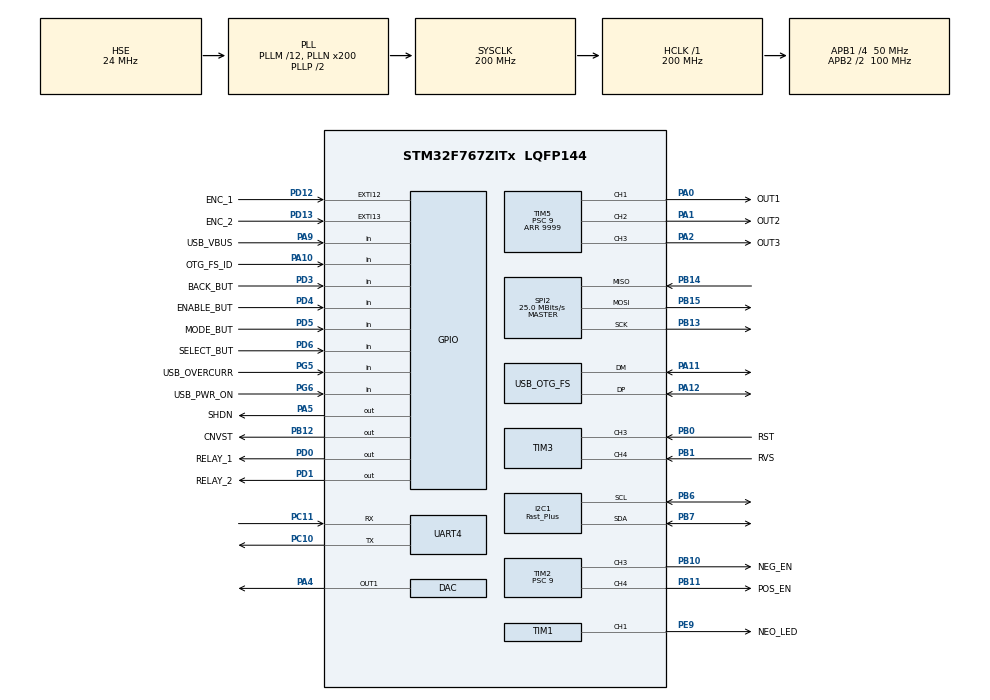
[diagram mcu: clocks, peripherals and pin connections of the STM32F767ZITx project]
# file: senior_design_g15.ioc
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Dma.Request0=TIM5_CH2
Dma.Request1=TIM5_CH3/UP
Dma.Request2=TIM2_UP/CH3
Dma.Request3=TIM2_CH2/CH4
Dma.Request4=TIM1_CH1
Dma.TIM1_CH1.4.Direction=DMA_MEMORY_TO_PERIPH
Dma.TIM1_CH1.4.FIFOMode=DMA_FIFOMODE_DISABLE
Dma.TIM1_CH1.4.Instance=DMA2_Stream1
Dma.TIM1_CH1.4.MemDataAlignment=DMA_MDATAALIGN_HALFWORD
Dma.TIM1_CH1.4.MemInc=DMA_MINC_ENABLE
Dma.TIM1_CH1.4.Mode=DMA_NORMAL
Dma.TIM1_CH1.4.PeriphDataAlignment=DMA_PDATAALIGN_HALFWORD
Dma.TIM1_CH1.4.PeriphInc=DMA_PINC_DISABLE
Dma.TIM1_CH1.4.Priority=DMA_PRIORITY_LOW
Dma.TIM2_CH2/CH4.3.Direction=DMA_MEMORY_TO_PERIPH
Dma.TIM2_CH2/CH4.3.FIFOMode=DMA_FIFOMODE_DISABLE
Dma.TIM2_CH2/CH4.3.Instance=DMA1_Stream6
Dma.TIM2_CH2/CH4.3.MemDataAlignment=DMA_MDATAALIGN_WORD
Dma.TIM2_CH2/CH4.3.MemInc=DMA_MINC_ENABLE
Dma.TIM2_CH2/CH4.3.Mode=DMA_CIRCULAR
Dma.TIM2_CH2/CH4.3.PeriphDataAlignment=DMA_PDATAALIGN_WORD
Dma.TIM2_CH2/CH4.3.PeriphInc=DMA_PINC_DISABLE
Dma.TIM2_CH2/CH4.3.Priority=DMA_PRIORITY_LOW
Dma.TIM2_UP/CH3.2.Direction=DMA_MEMORY_TO_PERIPH
Dma.TIM2_UP/CH3.2.FIFOMode=DMA_FIFOMODE_DISABLE
Dma.TIM2_UP/CH3.2.Instance=DMA1_Stream1
Dma.TIM2_UP/CH3.2.MemDataAlignment=DMA_MDATAALIGN_WORD
Dma.TIM2_UP/CH3.2.MemInc=DMA_MINC_ENABLE
Dma.TIM2_UP/CH3.2.Mode=DMA_CIRCULAR
Dma.TIM2_UP/CH3.2.PeriphDataAlignment=DMA_PDATAALIGN_WORD
Dma.TIM2_UP/CH3.2.PeriphInc=DMA_PINC_DISABLE
Dma.TIM2_UP/CH3.2.Priority=DMA_PRIORITY_LOW
Dma.TIM5_CH2.0.Direction=DMA_MEMORY_TO_PERIPH
Dma.TIM5_CH2.0.FIFOMode=DMA_FIFOMODE_DISABLE
Dma.TIM5_CH2.0.Instance=DMA1_Stream4
Dma.TIM5_CH2.0.MemDataAlignment=DMA_MDATAALIGN_WORD
Dma.TIM5_CH2.0.MemInc=DMA_MINC_ENABLE
Dma.TIM5_CH2.0.Mode=DMA_CIRCULAR
Dma.TIM5_CH2.0.PeriphDataAlignment=DMA_PDATAALIGN_WORD
Dma.TIM5_CH2.0.PeriphInc=DMA_PINC_DISABLE
Dma.TIM5_CH2.0.Priority=DMA_PRIORITY_LOW
Dma.TIM5_CH3/UP.1.Direction=DMA_MEMORY_TO_PERIPH
Dma.TIM5_CH3/UP.1.FIFOMode=DMA_FIFOMODE_DISABLE
Dma.TIM5_CH3/UP.1.Instance=DMA1_Stream0
Dma.TIM5_CH3/UP.1.MemDataAlignment=DMA_MDATAALIGN_WORD
Dma.TIM5_CH3/UP.1.MemInc=DMA_MINC_ENABLE
Dma.TIM5_CH3/UP.1.Mode=DMA_CIRCULAR
Dma.TIM5_CH3/UP.1.PeriphDataAlignment=DMA_PDATAALIGN_WORD
Dma.TIM5_CH3/UP.1.PeriphInc=DMA_PINC_DISABLE
Dma.TIM5_CH3/UP.1.Priority=DMA_PRIORITY_LOW
FREERTOS.MEMORY_ALLOCATION=1
FREERTOS.Queues01=vCom,250,uint8_t,0,Static,vComBuffer,vComControlBlock
FREERTOS.Tasks01=mainTask,0,1024,mainTask_entry,Default,NULL,Static,mainTaskBuffer,mainTaskControlBlock;displayTask_tas,-1,1024,displayTask_entry,Default,NULL,Static,displayTaskBuffer,displayTaskControlBlock;serial,0,1024,start_serial,Default,NULL,Static,myTask03Buffer,myTask03ControlBlock
FREERTOS.configENABLE_FPU=1
FREERTOS.configMINIMAL_STACK_SIZE=1024
I2C1.I2C_Speed_Mode=I2C_Fast_Plus
I2C1.Timing=0x0020081F
Mcu.Family=STM32F7
Mcu.Name=STM32F767ZITx
Mcu.Package=LQFP144
NVIC.DMA1_Stream0_IRQn=true\:5\:0\:false\:false\:true\:true\:true\:true\:true
NVIC.DMA1_Stream1_IRQn=true\:5\:0\:false\:false\:true\:true\:false\:true\:true
NVIC.DMA1_Stream4_IRQn=true\:5\:0\:false\:false\:true\:true\:true\:true\:true
NVIC.DMA1_Stream6_IRQn=true\:5\:0\:false\:false\:true\:true\:false\:true\:true
NVIC.DMA2_Stream1_IRQn=true\:5\:0\:false\:false\:true\:true\:false\:true\:true
NVIC.EXTI15_10_IRQn=true\:5\:0\:false\:false\:true\:true\:true\:true\:true
NVIC.OTG_FS_IRQn=true\:5\:0\:false\:false\:true\:true\:false\:true\:true
NVIC.PriorityGroup=NVIC_PRIORITYGROUP_4
NVIC.TIM6_DAC_IRQn=true\:15\:0\:false\:false\:true\:false\:false\:true\:true
NVIC.TimeBase=TIM6_DAC_IRQn
NVIC.TimeBaseIP=TIM6
PA0/WKUP.GPIO_Label=OUT1
PA0/WKUP.Signal=S_TIM5_CH1
PA1.GPIO_Label=OUT2
PA1.Signal=S_TIM5_CH2
PA10.GPIO_Label=OTG_FS_ID
PA10.Signal=GPIO_Input
PA11.Mode=Device_Only
PA11.Signal=USB_OTG_FS_DM
PA12.Mode=Device_Only
PA12.Signal=USB_OTG_FS_DP
PA2.GPIO_Label=OUT3
PA2.Signal=S_TIM5_CH3
PA4.Signal=COMP_DAC1_group
PA5.GPIO_Label=SHDN
PA5.Signal=GPIO_Output
PA9.GPIO_Label=USB_VBUS
PA9.GPIO_PuPd=GPIO_PULLDOWN
PA9.Signal=GPIO_Input
PB0.GPIO_Label=RST
PB0.Signal=S_TIM3_CH3
PB1.GPIO_Label=RVS
PB1.Signal=S_TIM3_CH4
PB10.GPIO_Label=NEG_EN
PB10.Signal=S_TIM2_CH3
PB11.GPIO_Label=POS_EN
PB11.Signal=S_TIM2_CH4
PB12.GPIO_Label=CNVST
PB12.Signal=GPIO_Output
PB13.Mode=Full_Duplex_Master
PB13.Signal=SPI2_SCK
PB14.Mode=Full_Duplex_Master
PB14.Signal=SPI2_MISO
PB15.Mode=Full_Duplex_Master
PB15.Signal=SPI2_MOSI
PB6.GPIO_Pu=GPIO_PULLUP
PB6.Mode=I2C
PB6.Signal=I2C1_SCL
PB7.GPIO_Pu=GPIO_PULLUP
PB7.Mode=I2C
PB7.Signal=I2C1_SDA
PC10.Mode=Asynchronous
PC10.Signal=UART4_TX
PC11.Mode=Asynchronous
PC11.Signal=UART4_RX
PD0.GPIO_Label=RELAY_1
PD0.Signal=GPIO_Output
PD1.GPIO_Label=RELAY_2
PD1.Signal=GPIO_Output
PD12.GPIO_Label=ENC_1
PD12.GPIO_ModeDefaultEXTI=GPIO_MODE_IT_RISING_FALLING
PD12.Signal=GPXTI12
PD13.GPIO_Label=ENC_2
PD13.GPIO_ModeDefaultEXTI=GPIO_MODE_IT_RISING_FALLING
PD13.Signal=GPXTI13
PD3.GPIO_Label=BACK_BUT
PD3.GPIO_PuPd=GPIO_PULLUP
PD3.Signal=GPIO_Input
PD4.GPIO_Label=ENABLE_BUT
PD4.GPIO_PuPd=GPIO_PULLUP
PD4.Signal=GPIO_Input
PD5.GPIO_Label=MODE_BUT
PD5.GPIO_PuPd=GPIO_PULLUP
PD5.Signal=GPIO_Input
PD6.GPIO_Label=SELECT_BUT
PD6.GPIO_PuPd=GPIO_PULLUP
PD6.Signal=GPIO_Input
PE9.GPIO_Label=NEO_LED
PE9.Signal=S_TIM1_CH1
PG5.GPIO_Label=USB_OVERCURR
PG5.Signal=GPIO_Input
PG6.GPIO_Label=USB_PWR_ON
PG6.Signal=GPIO_Input
PH0/OSC_IN.Mode=HSE-External-Clock-Source
PH0/OSC_IN.Signal=RCC_OSC_IN
PH1/OSC_OUT.Mode=HSE-External-Clock-Source
PH1/OSC_OUT.Signal=RCC_OSC_OUT
ProjectManager.HeapSize=0x600
ProjectManager.StackSize=0x400
ProjectManager.TargetToolchain=STM32CubeIDE
RCC.AHBFreq_Value=200000000
RCC.APB1CLKDivider=RCC_HCLK_DIV4
RCC.APB1Freq_Value=50000000
RCC.APB1TimFreq_Value=100000000
RCC.APB2CLKDivider=RCC_HCLK_DIV2
RCC.APB2Freq_Value=100000000
RCC.APB2TimFreq_Value=200000000
RCC.CortexFreq_Value=200000000
RCC.HCLKFreq_Value=200000000
RCC.HSE_VALUE=24000000
RCC.HSI_VALUE=16000000
RCC.LSE_VALUE=32768
RCC.PLL48CLockSelection=RCC_CLK48SOURCE_PLLSAIP
RCC.PLLM=12
RCC.PLLN=200
RCC.PLLQ=8
RCC.PLLSAIP=RCC_PLLSAIP_DIV8
RCC.SYSCLKFreq_VALUE=200000000
RCC.SYSCLKSource=RCC_SYSCLKSOURCE_PLLCLK
RCC.USBFreq_Value=48000000
RCC.VCOOutputFreq_Value=400000000
SH.COMP_DAC1_group.0=DAC_OUT1,DAC_OUT1
SH.S_TIM1_CH1.0=TIM1_CH1,PWM Generation1 CH1
SH.S_TIM2_CH3.0=TIM2_CH3,Output Compare3 CH3
SH.S_TIM2_CH4.0=TIM2_CH4,Output Compare4 CH4
SH.S_TIM3_CH3.0=TIM3_CH3,Input_Capture3_from_TI3
SH.S_TIM3_CH4.0=TIM3_CH4,Input_Capture4_from_TI4
SH.S_TIM5_CH1.0=TIM5_CH1,PWM Generation1 CH1
SH.S_TIM5_CH2.0=TIM5_CH2,Output Compare2 CH2
SH.S_TIM5_CH3.0=TIM5_CH3,Output Compare3 CH3
SPI2.BaudRatePrescaler=SPI_BAUDRATEPRESCALER_2
SPI2.CalculateBaudRate=25.0 MBits/s
SPI2.Direction=SPI_DIRECTION_2LINES
SPI2.Mode=SPI_MODE_MASTER
SPI2.VirtualType=VM_MASTER
TIM1.Channel-PWM\ Generation1\ CH1=TIM_CHANNEL_1
TIM1.OC1Preload_PWM=ENABLE
TIM1.OCFastMode_PWM-PWM\ Generation1\ CH1=TIM_OCFAST_DISABLE
TIM1.OCPolarity_1=TIM_OCPOLARITY_HIGH
TIM1.Period=29
TIM1.Prescaler=9
TIM1.Pulse-PWM\ Generation1\ CH1=0
TIM2.AutoReloadPreload=TIM_AUTORELOAD_PRELOAD_DISABLE
TIM2.Channel-Output\ Compare3\ CH3=TIM_CHANNEL_3
TIM2.Channel-Output\ Compare4\ CH4=TIM_CHANNEL_4
TIM2.Channel-PWM\ Generation3\ CH3=TIM_CHANNEL_3
TIM2.OC3Preload=DISABLE
TIM2.OC4Preload=DISABLE
TIM2.OCMode_3=TIM_OCMODE_TOGGLE
TIM2.OCMode_4=TIM_OCMODE_TOGGLE
TIM2.OCPolarity_3=TIM_OCPOLARITY_HIGH
TIM2.OCPolarity_4=TIM_OCPOLARITY_LOW
TIM2.Period=9999
TIM2.Prescaler=9
TIM2.TIM_MasterOutputTrigger=TIM_TRGO_ENABLE
TIM2.TIM_MasterSlaveMode=TIM_MASTERSLAVEMODE_ENABLE
TIM3.Channel-Input_Capture3_from_TI3=TIM_CHANNEL_3
TIM3.Channel-Input_Capture4_from_TI4=TIM_CHANNEL_4
TIM5.AutoReloadPreload=TIM_AUTORELOAD_PRELOAD_DISABLE
TIM5.Channel-Output\ Compare2\ CH2=TIM_CHANNEL_2
TIM5.Channel-Output\ Compare3\ CH3=TIM_CHANNEL_3
TIM5.Channel-PWM\ Generation1\ CH1=TIM_CHANNEL_1
TIM5.CounterMode=TIM_COUNTERMODE_UP
TIM5.OC1Preload_PWM=DISABLE
TIM5.OC2Preload=DISABLE
TIM5.OC3Preload=DISABLE
TIM5.OCFastMode_PWM-PWM\ Generation1\ CH1=TIM_OCFAST_DISABLE
TIM5.OCMode_2=TIM_OCMODE_TOGGLE
TIM5.OCMode_3=TIM_OCMODE_TOGGLE
TIM5.OCPolarity_1=TIM_OCPOLARITY_HIGH
TIM5.OCPolarity_2=TIM_OCPOLARITY_HIGH
TIM5.OCPolarity_3=TIM_OCPOLARITY_HIGH
TIM5.Period=9999
TIM5.Prescaler=9
TIM5.Pulse-Output\ Compare2\ CH2=0
TIM5.Pulse-Output\ Compare3\ CH3=0
TIM5.TIM_MasterOutputTrigger=TIM_TRGO_ENABLE
TIM5.TIM_MasterSlaveMode=TIM_MASTERSLAVEMODE_ENABLE
TIM8.Channel-Output\ Compare1\ No\ Output=TIM_CHANNEL_1
TIM8.Period=2000
TIM8.Prescaler=9
TIM8.Pulse-Output\ Compare1\ No\ Output=1000
TIM8.TIM_MasterOutputTrigger=TIM_TRGO_ENABLE
TIM8.TIM_MasterOutputTrigger2=TIM_TRGO2_ENABLE
TIM8.TIM_MasterSlaveMode=TIM_MASTERSLAVEMODE_DISABLE
USB_DEVICE.CLASS_NAME_FS=CDC
USB_DEVICE.PRODUCT_STRING_CDC_FS=MTJ Function Generator
USB_DEVICE.VirtualMode-CDC_FS=Cdc
USB_DEVICE.VirtualModeFS=Cdc_FS
USB_OTG_FS.VirtualMode=Device_Only
VP_FREERTOS_VS_CMSIS_V1.Mode=CMSIS_V1
VP_SYS_VS_tim6.Mode=TIM6
VP_TIM1_VS_ClockSourceINT.Mode=Internal
VP_TIM2_VS_ClockSourceINT.Mode=Internal
VP_TIM2_VS_ClockSourceITR.Mode=TriggerSource_ITR1
VP_TIM2_VS_ControllerModeTrigger.Mode=Trigger Mode
VP_TIM3_VS_ClockSourceINT.Mode=Internal
VP_TIM5_VS_ClockSourceINT.Mode=Internal
VP_TIM5_VS_ClockSourceITR.Mode=TriggerSource_ITR3
VP_TIM5_VS_ControllerModeTrigger.Mode=Trigger Mode
VP_TIM8_VS_ClockSourceINT.Mode=Internal
VP_TIM8_VS_no_output1.Mode=Output Compare1 No Output
VP_USB_DEVICE_VS_USB_DEVICE_CDC_FS.Mode=CDC_FS
board=custom

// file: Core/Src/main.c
/* USER CODE BEGIN Header */
/**
  ******************************************************************************
  * @file           : main.c
  * @brief          : Main program body
  ******************************************************************************
  * @attention
  *
  * Copyright (c) 2023 STMicroelectronics.
  * All rights reserved.
  *
  * This software is licensed under terms that can be found in the LICENSE file
  * in the root directory of this software component.
  * If no LICENSE file comes with this software, it is provided AS-IS.
  *
  ******************************************************************************
  */
/* USER CODE END Header */
#include "main.h"
#include "cmsis_os.h"
#include "usb_device.h"

/* USER CODE BEGIN Includes */
#include <stdint.h>
#include "main_task.h"
#include "display.h"
#include "serial.h"

/* USER CODE END Includes */

DAC_HandleTypeDef hdac;

I2C_HandleTypeDef hi2c1;

SPI_HandleTypeDef hspi2;

TIM_HandleTypeDef htim1;
TIM_HandleTypeDef htim2;
TIM_HandleTypeDef htim3;
TIM_HandleTypeDef htim5;
TIM_HandleTypeDef htim8;
DMA_HandleTypeDef hdma_tim1_ch1;
DMA_HandleTypeDef hdma_tim2_up_ch3;
DMA_HandleTypeDef hdma_tim2_ch2_ch4;
DMA_HandleTypeDef hdma_tim5_ch2;
DMA_HandleTypeDef hdma_tim5_ch3_up;

UART_HandleTypeDef huart4;

osThreadId mainTaskHandle;
uint32_t mainTaskBuffer[ 1024 ];
osStaticThreadDef_t mainTaskControlBlock;
osThreadId displayTask_tasHandle;
uint32_t displayTaskBuffer[ 1024 ];
osStaticThreadDef_t displayTaskControlBlock;
osThreadId serialHandle;
uint32_t myTask03Buffer[ 1024 ];
osStaticThreadDef_t myTask03ControlBlock;
osMessageQId vComHandle;
uint8_t vComBuffer[ 250 * sizeof( uint8_t ) ];
osStaticMessageQDef_t vComControlBlock;

void SystemClock_Config(void);
static void MX_GPIO_Init(void);
static void MX_TIM2_Init(void);
static void MX_SPI2_Init(void);
static void MX_I2C1_Init(void);
static void MX_TIM3_Init(void);
static void MX_DAC_Init(void);
static void MX_DMA_Init(void);
static void MX_TIM5_Init(void);
static void MX_TIM1_Init(void);
static void MX_UART4_Init(void);
static void MX_TIM8_Init(void);
void mainTask_entry(void const * argument);
void displayTask_entry(void const * argument);
void start_serial(void const * argument);

/* USER CODE BEGIN 0 */
uint32_t period_100us = 500;
/* USER CODE END 0 */

int main(void)
{

  /* MCU Configuration--------------------------------------------------------*/

  /* Reset of all peripherals, Initializes the Flash interface and the Systick. */
  HAL_Init();

  /* Configure the system clock */
  SystemClock_Config();

  /* USER CODE BEGIN SysInit */
  MX_DMA_Init();
  /* USER CODE END SysInit */

  /* Initialize all configured peripherals */
  MX_GPIO_Init();
  MX_TIM2_Init();
  MX_SPI2_Init();
  MX_I2C1_Init();
  MX_TIM3_Init();
  MX_DAC_Init();
  MX_DMA_Init();
  MX_TIM5_Init();
  MX_TIM1_Init();
  MX_UART4_Init();
  MX_TIM8_Init();

  /* Create the queue(s) */
  /* definition and creation of vCom */
  osMessageQStaticDef(vCom, 250, uint8_t, vComBuffer, &vComControlBlock);
  vComHandle = osMessageCreate(osMessageQ(vCom), NULL);

  /* Create the thread(s) */
  /* definition and creation of mainTask */
  osThreadStaticDef(mainTask, mainTask_entry, osPriorityNormal, 0, 1024, mainTaskBuffer, &mainTaskControlBlock);
  mainTaskHandle = osThreadCreate(osThread(mainTask), NULL);

  /* definition and creation of displayTask_tas */
  osThreadStaticDef(displayTask_tas, displayTask_entry, osPriorityBelowNormal, 0, 1024, displayTaskBuffer, &displayTaskControlBlock);
  displayTask_tasHandle = osThreadCreate(osThread(displayTask_tas), NULL);

  /* definition and creation of serial */
  osThreadStaticDef(serial, start_serial, osPriorityNormal, 0, 1024, myTask03Buffer, &myTask03ControlBlock);
  serialHandle = osThreadCreate(osThread(serial), NULL);

  /* Start scheduler */
  osKernelStart();

  /* We should never get here as control is now taken by the scheduler */
  /* Infinite loop */
  while (1)
  {

  }
}

void SystemClock_Config(void)
{
  RCC_OscInitTypeDef RCC_OscInitStruct = {0};
  RCC_ClkInitTypeDef RCC_ClkInitStruct = {0};

  /** Configure the main internal regulator output voltage
  */
  __HAL_RCC_PWR_CLK_ENABLE();
  __HAL_PWR_VOLTAGESCALING_CONFIG(PWR_REGULATOR_VOLTAGE_SCALE1);

  /** Initializes the RCC Oscillators according to the specified parameters
  * in the RCC_OscInitTypeDef structure.
  */
  RCC_OscInitStruct.OscillatorType = RCC_OSCILLATORTYPE_HSE;
  RCC_OscInitStruct.HSEState = RCC_HSE_BYPASS;
  RCC_OscInitStruct.PLL.PLLState = RCC_PLL_ON;
  RCC_OscInitStruct.PLL.PLLSource = RCC_PLLSOURCE_HSE;
  RCC_OscInitStruct.PLL.PLLM = 12;
  RCC_OscInitStruct.PLL.PLLN = 200;
  RCC_OscInitStruct.PLL.PLLP = RCC_PLLP_DIV2;
  RCC_OscInitStruct.PLL.PLLQ = 8;
  RCC_OscInitStruct.PLL.PLLR = 2;
  if (HAL_RCC_OscConfig(&RCC_OscInitStruct) != HAL_OK)
  {
    Error_Handler();
  }

  /** Activate the Over-Drive mode
  */
  if (HAL_PWREx_EnableOverDrive() != HAL_OK)
  {
    Error_Handler();
  }

  /** Initializes the CPU, AHB and APB buses clocks
  */
  RCC_ClkInitStruct.ClockType = RCC_CLOCKTYPE_HCLK|RCC_CLOCKTYPE_SYSCLK
                              |RCC_CLOCKTYPE_PCLK1|RCC_CLOCKTYPE_PCLK2;
  RCC_ClkInitStruct.SYSCLKSource = RCC_SYSCLKSOURCE_PLLCLK;
  RCC_ClkInitStruct.AHBCLKDivider = RCC_SYSCLK_DIV1;
  RCC_ClkInitStruct.APB1CLKDivider = RCC_HCLK_DIV4;
  RCC_ClkInitStruct.APB2CLKDivider = RCC_HCLK_DIV2;

  if (HAL_RCC_ClockConfig(&RCC_ClkInitStruct, FLASH_LATENCY_6) != HAL_OK)
  {
    Error_Handler();
  }
}

static void MX_DAC_Init(void)
{

  DAC_ChannelConfTypeDef sConfig = {0};

  /** DAC Initialization
  */
  hdac.Instance = DAC;
  if (HAL_DAC_Init(&hdac) != HAL_OK)
  {
    Error_Handler();
  }

  /** DAC channel OUT1 config
  */
  sConfig.DAC_Trigger = DAC_TRIGGER_NONE;
  sConfig.DAC_OutputBuffer = DAC_OUTPUTBUFFER_ENABLE;
  if (HAL_DAC_ConfigChannel(&hdac, &sConfig, DAC_CHANNEL_1) != HAL_OK)
  {
    Error_Handler();
  }

}

static void MX_I2C1_Init(void)
{

  hi2c1.Instance = I2C1;
  hi2c1.Init.Timing = 0x0020081F;
  hi2c1.Init.OwnAddress1 = 0;
  hi2c1.Init.AddressingMode = I2C_ADDRESSINGMODE_7BIT;
  hi2c1.Init.DualAddressMode = I2C_DUALADDRESS_DISABLE;
  hi2c1.Init.OwnAddress2 = 0;
  hi2c1.Init.OwnAddress2Masks = I2C_OA2_NOMASK;
  hi2c1.Init.GeneralCallMode = I2C_GENERALCALL_DISABLE;
  hi2c1.Init.NoStretchMode = I2C_NOSTRETCH_DISABLE;
  if (HAL_I2C_Init(&hi2c1) != HAL_OK)
  {
    Error_Handler();
  }

  /** Configure Analogue filter
  */
  if (HAL_I2CEx_ConfigAnalogFilter(&hi2c1, I2C_ANALOGFILTER_ENABLE) != HAL_OK)
  {
    Error_Handler();
  }

  /** Configure Digital filter
  */
  if (HAL_I2CEx_ConfigDigitalFilter(&hi2c1, 0) != HAL_OK)
  {
    Error_Handler();
  }

  /** I2C Enable Fast Mode Plus
  */
  HAL_I2CEx_EnableFastModePlus(I2C_FASTMODEPLUS_I2C1);

}

static void MX_SPI2_Init(void)
{

  /* SPI2 parameter configuration*/
  hspi2.Instance = SPI2;
  hspi2.Init.Mode = SPI_MODE_MASTER;
  hspi2.Init.Direction = SPI_DIRECTION_2LINES;
  hspi2.Init.DataSize = SPI_DATASIZE_4BIT;
  hspi2.Init.CLKPolarity = SPI_POLARITY_LOW;
  hspi2.Init.CLKPhase = SPI_PHASE_1EDGE;
  hspi2.Init.NSS = SPI_NSS_SOFT;
  hspi2.Init.BaudRatePrescaler = SPI_BAUDRATEPRESCALER_2;
  hspi2.Init.FirstBit = SPI_FIRSTBIT_MSB;
  hspi2.Init.TIMode = SPI_TIMODE_DISABLE;
  hspi2.Init.CRCCalculation = SPI_CRCCALCULATION_DISABLE;
  hspi2.Init.CRCPolynomial = 7;
  hspi2.Init.CRCLength = SPI_CRC_LENGTH_DATASIZE;
  hspi2.Init.NSSPMode = SPI_NSS_PULSE_ENABLE;
  if (HAL_SPI_Init(&hspi2) != HAL_OK)
  {
    Error_Handler();
  }

}

static void MX_TIM1_Init(void)
{

  TIM_ClockConfigTypeDef sClockSourceConfig = {0};
  TIM_MasterConfigTypeDef sMasterConfig = {0};
  TIM_OC_InitTypeDef sConfigOC = {0};
  TIM_BreakDeadTimeConfigTypeDef sBreakDeadTimeConfig = {0};

  htim1.Instance = TIM1;
  htim1.Init.Prescaler = 9;
  htim1.Init.CounterMode = TIM_COUNTERMODE_UP;
  htim1.Init.Period = 29;
  htim1.Init.ClockDivision = TIM_CLOCKDIVISION_DIV1;
  htim1.Init.RepetitionCounter = 0;
  htim1.Init.AutoReloadPreload = TIM_AUTORELOAD_PRELOAD_DISABLE;
  if (HAL_TIM_Base_Init(&htim1) != HAL_OK)
  {
    Error_Handler();
  }
  sClockSourceConfig.ClockSource = TIM_CLOCKSOURCE_INTERNAL;
  if (HAL_TIM_ConfigClockSource(&htim1, &sClockSourceConfig) != HAL_OK)
  {
    Error_Handler();
  }
  if (HAL_TIM_PWM_Init(&htim1) != HAL_OK)
  {
    Error_Handler();
  }
  sMasterConfig.MasterOutputTrigger = TIM_TRGO_RESET;
  sMasterConfig.MasterOutputTrigger2 = TIM_TRGO2_RESET;
  sMasterConfig.MasterSlaveMode = TIM_MASTERSLAVEMODE_DISABLE;
  if (HAL_TIMEx_MasterConfigSynchronization(&htim1, &sMasterConfig) != HAL_OK)
  {
    Error_Handler();
  }
  sConfigOC.OCMode = TIM_OCMODE_PWM1;
  sConfigOC.Pulse = 0;
  sConfigOC.OCPolarity = TIM_OCPOLARITY_HIGH;
  sConfigOC.OCNPolarity = TIM_OCNPOLARITY_HIGH;
  sConfigOC.OCFastMode = TIM_OCFAST_DISABLE;
  sConfigOC.OCIdleState = TIM_OCIDLESTATE_RESET;
  sConfigOC.OCNIdleState = TIM_OCNIDLESTATE_RESET;
  if (HAL_TIM_PWM_ConfigChannel(&htim1, &sConfigOC, TIM_CHANNEL_1) != HAL_OK)
  {
    Error_Handler();
  }
  sBreakDeadTimeConfig.OffStateRunMode = TIM_OSSR_DISABLE;
  sBreakDeadTimeConfig.OffStateIDLEMode = TIM_OSSI_DISABLE;
  sBreakDeadTimeConfig.LockLevel = TIM_LOCKLEVEL_OFF;
  sBreakDeadTimeConfig.DeadTime = 0;
  sBreakDeadTimeConfig.BreakState = TIM_BREAK_DISABLE;
  sBreakDeadTimeConfig.BreakPolarity = TIM_BREAKPOLARITY_HIGH;
  sBreakDeadTimeConfig.BreakFilter = 0;
  sBreakDeadTimeConfig.Break2State = TIM_BREAK2_DISABLE;
  sBreakDeadTimeConfig.Break2Polarity = TIM_BREAK2POLARITY_HIGH;
  sBreakDeadTimeConfig.Break2Filter = 0;
  sBreakDeadTimeConfig.AutomaticOutput = TIM_AUTOMATICOUTPUT_DISABLE;
  if (HAL_TIMEx_ConfigBreakDeadTime(&htim1, &sBreakDeadTimeConfig) != HAL_OK)
  {
    Error_Handler();
  }
  HAL_TIM_MspPostInit(&htim1);

}

static void MX_TIM2_Init(void)
{

  TIM_ClockConfigTypeDef sClockSourceConfig = {0};
  TIM_SlaveConfigTypeDef sSlaveConfig = {0};
  TIM_MasterConfigTypeDef sMasterConfig = {0};
  TIM_OC_InitTypeDef sConfigOC = {0};

  htim2.Instance = TIM2;
  htim2.Init.Prescaler = 9;
  htim2.Init.CounterMode = TIM_COUNTERMODE_UP;
  htim2.Init.Period = 9999;
  htim2.Init.ClockDivision = TIM_CLOCKDIVISION_DIV1;
  htim2.Init.AutoReloadPreload = TIM_AUTORELOAD_PRELOAD_DISABLE;
  if (HAL_TIM_Base_Init(&htim2) != HAL_OK)
  {
    Error_Handler();
  }
  sClockSourceConfig.ClockSource = TIM_CLOCKSOURCE_INTERNAL;
  if (HAL_TIM_ConfigClockSource(&htim2, &sClockSourceConfig) != HAL_OK)
  {
    Error_Handler();
  }
  if (HAL_TIM_OC_Init(&htim2) != HAL_OK)
  {
    Error_Handler();
  }
  sSlaveConfig.SlaveMode = TIM_SLAVEMODE_TRIGGER;
  sSlaveConfig.InputTrigger = TIM_TS_ITR1;
  if (HAL_TIM_SlaveConfigSynchro(&htim2, &sSlaveConfig) != HAL_OK)
  {
    Error_Handler();
  }
  sMasterConfig.MasterOutputTrigger = TIM_TRGO_ENABLE;
  sMasterConfig.MasterSlaveMode = TIM_MASTERSLAVEMODE_ENABLE;
  if (HAL_TIMEx_MasterConfigSynchronization(&htim2, &sMasterConfig) != HAL_OK)
  {
    Error_Handler();
  }
  sConfigOC.OCMode = TIM_OCMODE_TOGGLE;
  sConfigOC.Pulse = 0;
  sConfigOC.OCPolarity = TIM_OCPOLARITY_HIGH;
  sConfigOC.OCFastMode = TIM_OCFAST_DISABLE;
  if (HAL_TIM_OC_ConfigChannel(&htim2, &sConfigOC, TIM_CHANNEL_3) != HAL_OK)
  {
    Error_Handler();
  }
  sConfigOC.OCPolarity = TIM_OCPOLARITY_LOW;
  if (HAL_TIM_OC_ConfigChannel(&htim2, &sConfigOC, TIM_CHANNEL_4) != HAL_OK)
  {
    Error_Handler();
  }
  HAL_TIM_MspPostInit(&htim2);

}

static void MX_TIM3_Init(void)
{

  TIM_ClockConfigTypeDef sClockSourceConfig = {0};
  TIM_MasterConfigTypeDef sMasterConfig = {0};
  TIM_IC_InitTypeDef sConfigIC = {0};

  htim3.Instance = TIM3;
  htim3.Init.Prescaler = 0;
  htim3.Init.CounterMode = TIM_COUNTERMODE_UP;
  htim3.Init.Period = 65535;
  htim3.Init.ClockDivision = TIM_CLOCKDIVISION_DIV1;
  htim3.Init.AutoReloadPreload = TIM_AUTORELOAD_PRELOAD_DISABLE;
  if (HAL_TIM_Base_Init(&htim3) != HAL_OK)
  {
    Error_Handler();
  }
  sClockSourceConfig.ClockSource = TIM_CLOCKSOURCE_INTERNAL;
  if (HAL_TIM_ConfigClockSource(&htim3, &sClockSourceConfig) != HAL_OK)
  {
    Error_Handler();
  }
  if (HAL_TIM_IC_Init(&htim3) != HAL_OK)
  {
    Error_Handler();
  }
  sMasterConfig.MasterOutputTrigger = TIM_TRGO_RESET;
  sMasterConfig.MasterSlaveMode = TIM_MASTERSLAVEMODE_DISABLE;
  if (HAL_TIMEx_MasterConfigSynchronization(&htim3, &sMasterConfig) != HAL_OK)
  {
    Error_Handler();
  }
  sConfigIC.ICPolarity = TIM_INPUTCHANNELPOLARITY_RISING;
  sConfigIC.ICSelection = TIM_ICSELECTION_DIRECTTI;
  sConfigIC.ICPrescaler = TIM_ICPSC_DIV1;
  sConfigIC.ICFilter = 0;
  if (HAL_TIM_IC_ConfigChannel(&htim3, &sConfigIC, TIM_CHANNEL_3) != HAL_OK)
  {
    Error_Handler();
  }
  if (HAL_TIM_IC_ConfigChannel(&htim3, &sConfigIC, TIM_CHANNEL_4) != HAL_OK)
  {
    Error_Handler();
  }

}

static void MX_TIM5_Init(void)
{

  TIM_ClockConfigTypeDef sClockSourceConfig = {0};
  TIM_SlaveConfigTypeDef sSlaveConfig = {0};
  TIM_MasterConfigTypeDef sMasterConfig = {0};
  TIM_OC_InitTypeDef sConfigOC = {0};

  htim5.Instance = TIM5;
  htim5.Init.Prescaler = 9;
  htim5.Init.CounterMode = TIM_COUNTERMODE_UP;
  htim5.Init.Period = 9999;
  htim5.Init.ClockDivision = TIM_CLOCKDIVISION_DIV1;
  htim5.Init.AutoReloadPreload = TIM_AUTORELOAD_PRELOAD_DISABLE;
  if (HAL_TIM_Base_Init(&htim5) != HAL_OK)
  {
    Error_Handler();
  }
  sClockSourceConfig.ClockSource = TIM_CLOCKSOURCE_INTERNAL;
  if (HAL_TIM_ConfigClockSource(&htim5, &sClockSourceConfig) != HAL_OK)
  {
    Error_Handler();
  }
  if (HAL_TIM_PWM_Init(&htim5) != HAL_OK)
  {
    Error_Handler();
  }
  if (HAL_TIM_OC_Init(&htim5) != HAL_OK)
  {
    Error_Handler();
  }
  sSlaveConfig.SlaveMode = TIM_SLAVEMODE_TRIGGER;
  sSlaveConfig.InputTrigger = TIM_TS_ITR3;
  if (HAL_TIM_SlaveConfigSynchro(&htim5, &sSlaveConfig) != HAL_OK)
  {
    Error_Handler();
  }
  sMasterConfig.MasterOutputTrigger = TIM_TRGO_ENABLE;
  sMasterConfig.MasterSlaveMode = TIM_MASTERSLAVEMODE_ENABLE;
  if (HAL_TIMEx_MasterConfigSynchronization(&htim5, &sMasterConfig) != HAL_OK)
  {
    Error_Handler();
  }
  sConfigOC.OCMode = TIM_OCMODE_PWM1;
  sConfigOC.Pulse = 0;
  sConfigOC.OCPolarity = TIM_OCPOLARITY_HIGH;
  sConfigOC.OCFastMode = TIM_OCFAST_DISABLE;
  if (HAL_TIM_PWM_ConfigChannel(&htim5, &sConfigOC, TIM_CHANNEL_1) != HAL_OK)
  {
    Error_Handler();
  }
  __HAL_TIM_DISABLE_OCxPRELOAD(&htim5, TIM_CHANNEL_1);
  sConfigOC.OCMode = TIM_OCMODE_TOGGLE;
  if (HAL_TIM_OC_ConfigChannel(&htim5, &sConfigOC, TIM_CHANNEL_2) != HAL_OK)
  {
    Error_Handler();
  }
  if (HAL_TIM_OC_ConfigChannel(&htim5, &sConfigOC, TIM_CHANNEL_3) != HAL_OK)
  {
    Error_Handler();
  }
  HAL_TIM_MspPostInit(&htim5);

}

static void MX_TIM8_Init(void)
{

  TIM_ClockConfigTypeDef sClockSourceConfig = {0};
  TIM_MasterConfigTypeDef sMasterConfig = {0};
  TIM_OC_InitTypeDef sConfigOC = {0};
  TIM_BreakDeadTimeConfigTypeDef sBreakDeadTimeConfig = {0};

  htim8.Instance = TIM8;
  htim8.Init.Prescaler = 9;
  htim8.Init.CounterMode = TIM_COUNTERMODE_UP;
  htim8.Init.Period = 2000;
  htim8.Init.ClockDivision = TIM_CLOCKDIVISION_DIV1;
  htim8.Init.RepetitionCounter = 0;
  htim8.Init.AutoReloadPreload = TIM_AUTORELOAD_PRELOAD_DISABLE;
  if (HAL_TIM_Base_Init(&htim8) != HAL_OK)
  {
    Error_Handler();
  }
  sClockSourceConfig.ClockSource = TIM_CLOCKSOURCE_INTERNAL;
  if (HAL_TIM_ConfigClockSource(&htim8, &sClockSourceConfig) != HAL_OK)
  {
    Error_Handler();
  }
  if (HAL_TIM_OC_Init(&htim8) != HAL_OK)
  {
    Error_Handler();
  }
  sMasterConfig.MasterOutputTrigger = TIM_TRGO_ENABLE;
  sMasterConfig.MasterOutputTrigger2 = TIM_TRGO2_ENABLE;
  sMasterConfig.MasterSlaveMode = TIM_MASTERSLAVEMODE_DISABLE;
  if (HAL_TIMEx_MasterConfigSynchronization(&htim8, &sMasterConfig) != HAL_OK)
  {
    Error_Handler();
  }
  sConfigOC.OCMode = TIM_OCMODE_TIMING;
  sConfigOC.Pulse = 1000;
  sConfigOC.OCPolarity = TIM_OCPOLARITY_HIGH;
  sConfigOC.OCNPolarity = TIM_OCNPOLARITY_HIGH;
  sConfigOC.OCFastMode = TIM_OCFAST_DISABLE;
  sConfigOC.OCIdleState = TIM_OCIDLESTATE_RESET;
  sConfigOC.OCNIdleState = TIM_OCNIDLESTATE_RESET;
  if (HAL_TIM_OC_ConfigChannel(&htim8, &sConfigOC, TIM_CHANNEL_1) != HAL_OK)
  {
    Error_Handler();
  }
  sBreakDeadTimeConfig.OffStateRunMode = TIM_OSSR_DISABLE;
  sBreakDeadTimeConfig.OffStateIDLEMode = TIM_OSSI_DISABLE;
  sBreakDeadTimeConfig.LockLevel = TIM_LOCKLEVEL_OFF;
  sBreakDeadTimeConfig.DeadTime = 0;
  sBreakDeadTimeConfig.BreakState = TIM_BREAK_DISABLE;
  sBreakDeadTimeConfig.BreakPolarity = TIM_BREAKPOLARITY_HIGH;
  sBreakDeadTimeConfig.BreakFilter = 0;
  sBreakDeadTimeConfig.Break2State = TIM_BREAK2_DISABLE;
  sBreakDeadTimeConfig.Break2Polarity = TIM_BREAK2POLARITY_HIGH;
  sBreakDeadTimeConfig.Break2Filter = 0;
  sBreakDeadTimeConfig.AutomaticOutput = TIM_AUTOMATICOUTPUT_DISABLE;
  if (HAL_TIMEx_ConfigBreakDeadTime(&htim8, &sBreakDeadTimeConfig) != HAL_OK)
  {
    Error_Handler();
  }

}

static void MX_UART4_Init(void)
{

  huart4.Instance = UART4;
  huart4.Init.BaudRate = 115200;
  huart4.Init.WordLength = UART_WORDLENGTH_8B;
  huart4.Init.StopBits = UART_STOPBITS_1;
  huart4.Init.Parity = UART_PARITY_NONE;
  huart4.Init.Mode = UART_MODE_TX_RX;
  huart4.Init.HwFlowCtl = UART_HWCONTROL_NONE;
  huart4.Init.OverSampling = UART_OVERSAMPLING_16;
  huart4.Init.OneBitSampling = UART_ONE_BIT_SAMPLE_DISABLE;
  huart4.AdvancedInit.AdvFeatureInit = UART_ADVFEATURE_NO_INIT;
  if (HAL_UART_Init(&huart4) != HAL_OK)
  {
    Error_Handler();
  }

}

static void MX_DMA_Init(void)
{

  /* DMA controller clock enable */
  __HAL_RCC_DMA1_CLK_ENABLE();
  __HAL_RCC_DMA2_CLK_ENABLE();

  /* DMA interrupt init */
  /* DMA1_Stream0_IRQn interrupt configuration */
  HAL_NVIC_SetPriority(DMA1_Stream0_IRQn, 5, 0);
  HAL_NVIC_EnableIRQ(DMA1_Stream0_IRQn);
  /* DMA1_Stream1_IRQn interrupt configuration */
  HAL_NVIC_SetPriority(DMA1_Stream1_IRQn, 5, 0);
  HAL_NVIC_EnableIRQ(DMA1_Stream1_IRQn);
  /* DMA1_Stream4_IRQn interrupt configuration */
  HAL_NVIC_SetPriority(DMA1_Stream4_IRQn, 5, 0);
  HAL_NVIC_EnableIRQ(DMA1_Stream4_IRQn);
  /* DMA1_Stream6_IRQn interrupt configuration */
  HAL_NVIC_SetPriority(DMA1_Stream6_IRQn, 5, 0);
  HAL_NVIC_EnableIRQ(DMA1_Stream6_IRQn);
  /* DMA2_Stream1_IRQn interrupt configuration */
  HAL_NVIC_SetPriority(DMA2_Stream1_IRQn, 5, 0);
  HAL_NVIC_EnableIRQ(DMA2_Stream1_IRQn);

}

static void MX_GPIO_Init(void)
{
  GPIO_InitTypeDef GPIO_InitStruct = {0};

  /* GPIO Ports Clock Enable */
  __HAL_RCC_GPIOH_CLK_ENABLE();
  __HAL_RCC_GPIOA_CLK_ENABLE();
  __HAL_RCC_GPIOB_CLK_ENABLE();
  __HAL_RCC_GPIOE_CLK_ENABLE();
  __HAL_RCC_GPIOD_CLK_ENABLE();
  __HAL_RCC_GPIOG_CLK_ENABLE();
  __HAL_RCC_GPIOC_CLK_ENABLE();

  /*Configure GPIO pin Output Level */
  HAL_GPIO_WritePin(SHDN_GPIO_Port, SHDN_Pin, GPIO_PIN_RESET);

  /*Configure GPIO pin Output Level */
  HAL_GPIO_WritePin(CNVST_GPIO_Port, CNVST_Pin, GPIO_PIN_RESET);

  /*Configure GPIO pin Output Level */
  HAL_GPIO_WritePin(GPIOD, RELAY_1_Pin|RELAY_2_Pin, GPIO_PIN_RESET);

  /*Configure GPIO pin : SHDN_Pin */
  GPIO_InitStruct.Pin = SHDN_Pin;
  GPIO_InitStruct.Mode = GPIO_MODE_OUTPUT_PP;
  GPIO_InitStruct.Pull = GPIO_NOPULL;
  GPIO_InitStruct.Speed = GPIO_SPEED_FREQ_LOW;
  HAL_GPIO_Init(SHDN_GPIO_Port, &GPIO_InitStruct);

  /*Configure GPIO pin : CNVST_Pin */
  GPIO_InitStruct.Pin = CNVST_Pin;
  GPIO_InitStruct.Mode = GPIO_MODE_OUTPUT_PP;
  GPIO_InitStruct.Pull = GPIO_NOPULL;
  GPIO_InitStruct.Speed = GPIO_SPEED_FREQ_LOW;
  HAL_GPIO_Init(CNVST_GPIO_Port, &GPIO_InitStruct);

  /*Configure GPIO pins : ENC_1_Pin ENC_2_Pin */
  GPIO_InitStruct.Pin = ENC_1_Pin|ENC_2_Pin;
  GPIO_InitStruct.Mode = GPIO_MODE_IT_RISING_FALLING;
  GPIO_InitStruct.Pull = GPIO_NOPULL;
  HAL_GPIO_Init(GPIOD, &GPIO_InitStruct);

  /*Configure GPIO pins : USB_OVERCURR_Pin USB_PWR_ON_Pin */
  GPIO_InitStruct.Pin = USB_OVERCURR_Pin|USB_PWR_ON_Pin;
  GPIO_InitStruct.Mode = GPIO_MODE_INPUT;
  GPIO_InitStruct.Pull = GPIO_NOPULL;
  HAL_GPIO_Init(GPIOG, &GPIO_InitStruct);

  /*Configure GPIO pin : USB_VBUS_Pin */
  GPIO_InitStruct.Pin = USB_VBUS_Pin;
  GPIO_InitStruct.Mode = GPIO_MODE_INPUT;
  GPIO_InitStruct.Pull = GPIO_PULLDOWN;
  HAL_GPIO_Init(USB_VBUS_GPIO_Port, &GPIO_InitStruct);

  /*Configure GPIO pin : OTG_FS_ID_Pin */
  GPIO_InitStruct.Pin = OTG_FS_ID_Pin;
  GPIO_InitStruct.Mode = GPIO_MODE_INPUT;
  GPIO_InitStruct.Pull = GPIO_NOPULL;
  HAL_GPIO_Init(OTG_FS_ID_GPIO_Port, &GPIO_InitStruct);

  /*Configure GPIO pins : RELAY_1_Pin RELAY_2_Pin */
  GPIO_InitStruct.Pin = RELAY_1_Pin|RELAY_2_Pin;
  GPIO_InitStruct.Mode = GPIO_MODE_OUTPUT_PP;
  GPIO_InitStruct.Pull = GPIO_NOPULL;
  GPIO_InitStruct.Speed = GPIO_SPEED_FREQ_LOW;
  HAL_GPIO_Init(GPIOD, &GPIO_InitStruct);

  /*Configure GPIO pins : BACK_BUT_Pin ENABLE_BUT_Pin MODE_BUT_Pin SELECT_BUT_Pin */
  GPIO_InitStruct.Pin = BACK_BUT_Pin|ENABLE_BUT_Pin|MODE_BUT_Pin|SELECT_BUT_Pin;
  GPIO_InitStruct.Mode = GPIO_MODE_INPUT;
  GPIO_InitStruct.Pull = GPIO_PULLUP;
  HAL_GPIO_Init(GPIOD, &GPIO_InitStruct);

  /* EXTI interrupt init*/
  HAL_NVIC_SetPriority(EXTI15_10_IRQn, 5, 0);
  HAL_NVIC_EnableIRQ(EXTI15_10_IRQn);

}

void mainTask_entry(void const * argument)
{
  /* init code for USB_DEVICE */
  MX_USB_DEVICE_Init();
  /* USER CODE BEGIN 5 */
  /* Infinite loop */
  for(;;)
  {
	 main_task();
    osDelay(100);
  }
  /* USER CODE END 5 */
}

void displayTask_entry(void const * argument)
{
  /* USER CODE BEGIN displayTask_entry */
  /* Infinite loop */
  for(;;)
  {
	  display_task();
    osDelay(1);
  }
  /* USER CODE END displayTask_entry */
}

void start_serial(void const * argument)
{
  /* USER CODE BEGIN start_serial */
  /* Infinite loop */
  for(;;)
  {
	  runSerial();
    osDelay(1);
  }
  /* USER CODE END start_serial */
}

void HAL_TIM_PeriodElapsedCallback(TIM_HandleTypeDef *htim)
{
  if (htim->Instance == TIM6) {
    HAL_IncTick();
  }
}

void Error_Handler(void)
{
  __disable_irq();
  while (1)
  {
  }
}
